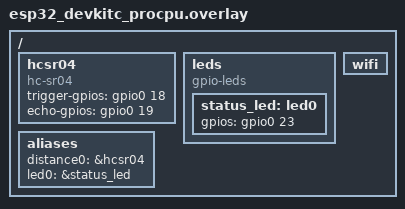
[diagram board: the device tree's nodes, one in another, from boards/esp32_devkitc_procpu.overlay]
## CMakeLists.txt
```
# SPDX-License-Identifier: Apache-2.0

cmake_minimum_required(VERSION 3.20.0)

find_package(Zephyr REQUIRED HINTS $ENV{ZEPHYR_BASE})
project(demo_wifi)

FILE(GLOB app_sources src/*.c)
target_sources(app PRIVATE ${app_sources})
```

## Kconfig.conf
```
# Required to get an IP address from DHCP
CONFIG_ESP32_WIFI_STA_AUTO_DHCPV4=y
CONFIG_ESP32_WIFI_ENABLE_WPA3_SAE=y
CONFIG_WIFI_ESP32_PM_NONE=y


# Use system heap (instead of runtime) for WiFi
CONFIG_ESP_WIFI_HEAP_SYSTEM=y
CONFIG_HEAP_MEM_POOL_SIZE=51200
```

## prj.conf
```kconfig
# Increase stack memory to avoid crashes
CONFIG_MAIN_STACK_SIZE=4096

# Enable WiFi
CONFIG_WIFI=y


# Networking config
CONFIG_NETWORKING=y
CONFIG_NET_IPV4=y
CONFIG_NET_IPV6=y
CONFIG_NET_TCP=y
CONFIG_NET_SOCKETS=y
CONFIG_ESP32_WIFI_ENABLE_WPA3_SAE=y
CONFIG_MQTT_LIB=y
CONFIG_NET_L2_WIFI_MGMT=y
CONFIG_NET_MGMT=y
CONFIG_NET_MGMT_EVENT=y
CONFIG_WIFI_ESP32=y
CONFIG_NET_IF_UNICAST_IPV4_ADDR_COUNT=1
CONFIG_NET_IF_MAX_IPV4_COUNT=1


# Get IPv4 address from DHCP
CONFIG_NET_DHCPV4=y

# Enable DNS resolver
CONFIG_DNS_RESOLVER=y

# How long to wait for e.g. DHCP to provide an IP address (seconds)
CONFIG_NET_CONFIG_INIT_TIMEOUT=30

# Network debug config
CONFIG_NET_LOG=y

# Enable Ethernet (required for WiFi)
CONFIG_NET_L2_ETHERNET=y

# Console Logs
CONFIG_CONSOLE=y
CONFIG_PRINTK=y


# Posix Threads
CONFIG_POSIX_API=y
CONFIG_THREAD_STACK_INFO=y
CONFIG_DYNAMIC_THREAD=y
CONFIG_DYNAMIC_THREAD_POOL_SIZE=8
CONFIG_POSIX_THREAD_THREADS_MAX=8

# Distance Sensor
CONFIG_GPIO=y
CONFIG_LOG=y
CONFIG_CBPRINTF_FP_SUPPORT=y
CONFIG_SENSOR=y
CONFIG_HC_SR04=y

# K_events
CONFIG_EVENTS=y

# UART
CONFIG_UART_CONSOLE=y
CONFIG_SERIAL=y

# JSON
CONFIG_JSON_LIBRARY=y
```

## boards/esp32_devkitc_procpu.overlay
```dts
#include <zephyr/dt-bindings/gpio/gpio.h>

/ {
    hcsr04: hcsr04 {
        compatible = "hc-sr04";
        status = "okay";

        trigger-gpios = <&gpio0 18 GPIO_ACTIVE_HIGH>;
        echo-gpios = <&gpio0 19 GPIO_ACTIVE_HIGH>;
        
    };

    leds {
        compatible = "gpio-leds";

        status_led: led0 {
            gpios = <&gpio0 23 GPIO_ACTIVE_HIGH>;
        };
    };

    wifi: wifi {
        status = "okay";
    };

    aliases {
        distance0 = &hcsr04;
        led0 = &status_led;
    };

   
};
```

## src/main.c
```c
#include <zephyr/kernel.h>
#include <semaphore.h>
#include <pthread.h>
#include <zephyr/net/net_if.h>
#include <zephyr/net/net_event.h>
#include <zephyr/net/wifi_mgmt.h>
#include <zephyr/net/dhcpv4.h>

#include "sync.h"
#include "mqtt.h"
#include "wifi.h"
#include "peripherals.h"
#include "uart.h"
#include "commands.h"

#define STACK_SIZE_MQTT 4096
#define STACK_SIZE_SENSOR 2048
#define STACK_SIZE_UART 4096
#define STACK_SIZE_COMM 4096

K_THREAD_STACK_DEFINE(mqtt_stack, STACK_SIZE_MQTT);
K_THREAD_STACK_DEFINE(distSen_stack, STACK_SIZE_SENSOR);
K_THREAD_STACK_DEFINE(uart_stack, STACK_SIZE_UART);
K_THREAD_STACK_DEFINE(comm_stack, STACK_SIZE_COMM);

struct k_thread ids[5];

int main(void)
{
    printk("Starting app\n");
    k_sem_init(&wifi_ready, 0, 1);
    k_sem_init(&ipv4_ready, 0, 1);
    wifi_init();
    wifi_connect();
    mqtt_init();


    k_thread_create(&ids[0],
                    mqtt_stack,
                    K_THREAD_STACK_SIZEOF(mqtt_stack),
                    thread_mqtt,
                    NULL, NULL, NULL,
                    2,           
                    0,          
                    K_NO_WAIT);
    
    k_thread_create(&ids[1],
                    distSen_stack,
                    K_THREAD_STACK_SIZEOF(distSen_stack),
                    thread_distSen,
                    NULL, NULL, NULL,
                    3,           
                    0,           
                    K_NO_WAIT);

    k_thread_create(&ids[2],
                    uart_stack,
                    K_THREAD_STACK_SIZEOF(uart_stack),
                    thread_uart,
                    NULL, NULL, NULL,
                    5,           
                    0,           
                    K_NO_WAIT);
    
    k_thread_create(&ids[3],
                    comm_stack,
                    K_THREAD_STACK_SIZEOF(comm_stack),
                    thread_comm,
                    NULL, NULL, NULL,
                    4,           
                    0,           
                    K_NO_WAIT);

    while (1) {
        k_sleep(K_SECONDS(2));
    }
}
```

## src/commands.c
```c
#include "commands.h"
void thread_comm(void *p1, void *p2, void *p3)
{
    char msg[256];
    static const struct gpio_dt_spec led = GPIO_DT_SPEC_GET(LED_NODE, gpios);
    if (!gpio_is_ready_dt(&led)) {
        printk("LED not ready\n");
        return;
    }
    gpio_pin_configure_dt(&led, GPIO_OUTPUT_INACTIVE);
    
    printk("Comm awaiting MQTT readyness...\n");
    k_event_wait(&sys_events,MQTT_READY_EVENT,false,K_FOREVER);

    while(1)
    {
        k_msgq_get(&comm_msgq, msg, K_FOREVER);
        printk("msg received: %s\n",msg);
        if (strcmp(msg, "ledOn") == 0) 
        {
            gpio_pin_set_dt(&led, 1);
            printk("LED ON\n");
        } 
        else if (strcmp(msg, "ledOff") == 0) {
            gpio_pin_set_dt(&led, 0);
            printk("LED OFF\n");
        }
    }
}
```

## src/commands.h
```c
#include <zephyr/kernel.h>
#include <zephyr/drivers/gpio.h>
#include <string.h>

#include "sync.h"

void thread_comm(void *p1, void *p2, void *p3);

#define LED_NODE DT_ALIAS(led0)
```

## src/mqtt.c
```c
#include "mqtt.h"
#include "sync.h"

static struct mqtt_client client;
static struct sockaddr_storage broker;
static uint32_t mqtt_rx_count = 0;

static uint8_t rx_buffer[256];
static uint8_t tx_buffer[256];
static uint16_t next_msg_id = 1;
char msgSend[MSG_SIZE];
char msgRec[MSG_SIZE];
bool mqttReady = false;

int mqtt_subscribe_topic(const char *topic);
int mqtt_publish_text(const char *topic,
                      const char *payload);
void parseComm(char *arr);
int get_text_field(const uint8_t *payload, size_t payload_len,
                   char *output, size_t output_len);

void build_json(char *out, size_t len,
                const char *id,
                const char *sender,
                const char *text)
{
    snprintf(out, len,
             "{\"id\":\"%s\",\"sender\":\"%s\",\"text\":\"%s\"}",
             id, sender, text);
}


                      
static void mqtt_event_handler(struct mqtt_client *client,
                               const struct mqtt_evt *evt)
{
    switch (evt->type) {
        case MQTT_EVT_CONNACK:
            if (evt->result == 0) 
                {
                    printk("MQTT connected!\n");
                    printk("POSTING TO EVENT=%p\n", &sys_events);
                    k_event_post(&sys_events, MQTT_READY_EVENT);
                    int rc = mqtt_subscribe_topic(UI_SUB);
                    printk("subscribe rc=%d\n", rc);
                    mqtt_publish_text(MCU_PUB, "{\"id\":\"mcu1\",\"sender\":\"mcu\",\"text\":\"MCU Joined\"}");
                    mqttReady = true;
                } 
            else 
                {printk("MQTT connection failed (%d)\n", evt->result);}
            break;

        case MQTT_EVT_DISCONNECT:
            printk("MQTT disconnected.\n");
            break;

        case MQTT_EVT_PUBLISH:
            printk("MQTT publish event #%u\n", ++mqtt_rx_count);
            uint8_t payload[256];
            char comm[256];
            int ret = mqtt_read_publish_payload(client,payload,sizeof(payload));
            if (ret < 0) {
                printk("read failed: %d\n", ret);
                break;
            }
            printk("msg received: %s\n",(char*)payload);
            int commRet = get_text_field(payload,strlen(payload),comm,sizeof(comm));
            if(!commRet) k_msgq_put(&comm_msgq, comm, K_FOREVER);
            break;
        
        default:
            break;
        }

}
    
void mqtt_init(void)
{
    mqtt_client_init(&client);

    client.evt_cb = mqtt_event_handler;
    client.client_id.utf8 = (uint8_t *)"esp32_client";
    client.client_id.size = strlen("esp32_client");
    client.password = NULL;
    client.user_name = NULL;
    client.keepalive = 45;
    client.protocol_version = MQTT_VERSION_3_1_1;
    client.rx_buf = rx_buffer;
    client.rx_buf_size = sizeof(rx_buffer);
    client.tx_buf = tx_buffer;
    client.tx_buf_size = sizeof(tx_buffer);

    struct sockaddr_in *broker4 =
        (struct sockaddr_in *)&broker;

    broker4->sin_family = AF_INET;
    broker4->sin_port = htons(MQTT_BROKER_PORT);

    zsock_inet_pton(AF_INET,
                    MQTT_BROKER_IP,
                    &broker4->sin_addr);

    client.broker = &broker;
    client.transport.type = MQTT_TRANSPORT_NON_SECURE;
}

static int mqtt_connect_to_broker(void)
{
    printk("Connecting to MQTT broker...\n");

    int ret = mqtt_connect(&client);

    if (ret) {
        printk("mqtt_connect() failed (%d)\n", ret);
    }

    return ret;
}

int mqtt_subscribe_topic(const char *topic)
{
    struct mqtt_topic sub_topic = {
        .topic = {
            .utf8 = (uint8_t *)topic,
            .size = strlen(topic),
        },
        .qos = MQTT_QOS_0_AT_MOST_ONCE,
    };

    const struct mqtt_subscription_list subs = {
        .list = &sub_topic,
        .list_count = 1,
        .message_id = next_msg_id++
    };

    return mqtt_subscribe(&client, &subs);
}

int mqtt_publish_text(const char *topic,
                      const char *payload)
{
    struct mqtt_publish_param param;
    
    memset(&param, 0, sizeof(param));
    param.message.topic.topic.utf8 = (uint8_t *)topic;
    param.message.topic.topic.size = strlen(topic);

    param.message.topic.qos = MQTT_QOS_0_AT_MOST_ONCE;
    param.message.payload.data = (uint8_t *)payload;
    param.message.payload.len = strlen(payload);

    param.message_id = 0;

    param.dup_flag = 0;
    param.retain_flag = 0;
    return mqtt_publish(&client, &param);
}

int get_text_field(const uint8_t *payload, size_t payload_len,
                   char *output, size_t output_len)
{
    const char key[] = "\"text\":\"";
    size_t key_len = sizeof(key) - 1;
    const uint8_t *start = NULL;
    for (size_t i = 0; i <= payload_len - key_len; i++) {
        if (memcmp(&payload[i], key, key_len) == 0) {
            start = &payload[i + key_len];
            break;
        }
    }
    if (start == NULL) {
        return -1; 
    }
    size_t i = 0;
    while (i < output_len - 1 &&
           (start[i] != '"') &&
           ((start + i) < (payload + payload_len))) {
        output[i] = start[i];
        i++;
    }
    output[i] = '\0';
    return 0;
}

void thread_mqtt(void *p1, void *p2, void *p3)
{
    printk("Awaiting Wifi connection...\n");
    k_sem_take(&wifi_ready,K_FOREVER);
    k_sem_take(&ipv4_ready,K_FOREVER);
    printk("Wifi connected. Starting MQTT...\n");

    if (mqtt_connect_to_broker()) {
        return;
    }

    while (1) {
        if(mqttReady)
        {
            char json[MSG_SIZE];
            k_msgq_get(&mqtt_msgq, msgSend, K_FOREVER);
            build_json(json,sizeof(json),MCU_ID,SENDER,msgSend);
            mqtt_publish_text(MCU_PUB, json);
        }
        mqtt_input(&client);
        mqtt_live(&client);
        k_sleep(K_MSEC(100));
    }

    return;
}
```

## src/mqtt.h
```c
#ifndef MQTT_H
#define MQTT_H

#include <pthread.h>
#include <semaphore.h>
#include <string.h>

#include <zephyr/net/socket.h>
#include <zephyr/net/mqtt.h>
#include <string.h>
#include <stdint.h>

#define MQTT_BROKER_IP   "10.208.10.41"
#define MQTT_BROKER_PORT 1883
#define MCU_PUB "mcu/pub"
#define UI_SUB "ui/pub"
#define MCU_ID "mcu1"
#define SENDER "mcu"

void mqtt_init(void);
void thread_mqtt(void *p1, void *p2, void *p3);

#endif
```

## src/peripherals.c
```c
#include "peripherals.h"

#define HCSR04_NODE DT_ALIAS(distance0)

void thread_distSen(void *p1, void *p2, void *p3)
{
    const struct device *sensor = DEVICE_DT_GET(HCSR04_NODE);

    if (!device_is_ready(sensor)) {
        printk("HC-SR04 Sensor Ready.\n");
        return;
    }

    printk("HC-SR04 sensor waiting MQTT readyness...\n");
    //printk("WAITING ON EVENT PTR=%p\n", &sys_events);
    k_event_wait(&sys_events,MQTT_READY_EVENT,false,K_FOREVER);
    printk("HC-SR04 sensor beginning measuring.\n");

    while (1) {
        struct sensor_value distancia;
        int ret;

        ret = sensor_sample_fetch(sensor);
        if (ret < 0) {
            printk("Error fetching sample: %d\n", ret);
            k_msleep(1700);
            continue;
        }

        ret = sensor_channel_get(sensor,
                                 SENSOR_CHAN_DISTANCE,
                                 &distancia);
        if (ret < 0) {
            printk("Error measuring Distance: %d\n", ret);
            k_msleep(1700);
            continue;
        }
        
        char msg[MSG_SIZE];

        snprintf(msg, sizeof(msg),
                "Distance: %d.%06d m",
                distancia.val1,
                distancia.val2);

        k_msgq_put(&mqtt_msgq, msg, K_FOREVER);

        k_msleep(1700);
    }

    return;
}
```

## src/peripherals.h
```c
#ifndef PERIPHERALS_H
#define PERIPHERALS_H

#include <zephyr/kernel.h>
#include <zephyr/device.h>
#include <zephyr/drivers/sensor.h>
#include <zephyr/sys/printk.h>

#include "sync.h"

void thread_distSen(void *p1, void *p2, void *p3);

#endif
```

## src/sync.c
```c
#include "sync.h"

struct k_sem wifi_ready;
struct k_sem ipv4_ready;
K_MSGQ_DEFINE(mqtt_msgq, MSG_SIZE, 10, 4);
K_MSGQ_DEFINE(comm_msgq, MSG_SIZE, 10, 4);
//K_MSGQ_DEFINE(mqtt_msgq, 256, 10, 4);
K_EVENT_DEFINE(sys_events);
```

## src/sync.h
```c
#ifndef SYNC_H
#define SYNC_H

#include <zephyr/kernel.h>

#define MSG_SIZE 256

extern struct k_sem  wifi_ready;
extern struct k_sem ipv4_ready;

extern struct k_msgq mqtt_msgq;
extern struct k_msgq comm_msgq;

extern struct k_event sys_events;
#define MQTT_READY_EVENT BIT(0)

#endif
```

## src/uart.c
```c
#include "uart.h"

void thread_uart(void *p1, void *p2, void *p3)
{
    const struct device *uart = DEVICE_DT_GET(UART_DEV_NODE);

    char buf[MSG_SIZE];
    int idx = 0;
    uint8_t c;

    if (!device_is_ready(uart)) {
        printk("UART device not ready!\n");
        return;
    }

    printk("UART awaiting MQTT readyness...\n");
    k_event_wait(&sys_events,MQTT_READY_EVENT,false,K_FOREVER);

    while (1) {
        if (uart_poll_in(uart, &c) == 0) {
            if (c == '\r' || c == '\n') {
                if (idx > 0) {
                    buf[idx] = '\0';
                    printk("\n");
                    k_msgq_put(&mqtt_msgq, buf, K_FOREVER);
                    idx = 0;
                }
                printk("uart> ");
            }
            else if ((c == '\b' || c == 127) && idx > 0) {
                idx--;
                printk("\b \b");
            }
            else if (idx < MSG_SIZE - 1) {
                buf[idx++] = c;
                printk("%c", c);
            }
        }
        k_sleep(K_MSEC(1));
    }
}
```

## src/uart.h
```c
#include <zephyr/device.h>
#include <zephyr/drivers/uart.h>

#include "sync.h"

void thread_uart(void *p1, void *p2, void *p3);

#define UART_DEV_NODE DT_CHOSEN(zephyr_console)
```

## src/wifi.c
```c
#include "wifi.h"

/* --- Event callback --- */

static struct net_mgmt_event_callback wifi_cb;
static struct net_mgmt_event_callback ipv4_cb;

void ipv4_event_handler(struct net_mgmt_event_callback *cb,
                               uint64_t event,
                               struct net_if *iface)
{
    printk("IP Received\n");
    k_sem_give(&ipv4_ready);
}

void wifi_event_handler(struct net_mgmt_event_callback *cb,
                               uint64_t event,
                               struct net_if *iface)
{
    printk("wifi is connected\n");
    k_sem_give(&wifi_ready);
}


void wifi_connect(void)
{
    struct net_if *iface = net_if_get_default();

    struct wifi_connect_req_params params = {
        .ssid = WIFI_SSID,
        .ssid_length = strlen(WIFI_SSID),
        .psk = WIFI_PSK,
        .psk_length = strlen(WIFI_PSK),
        .security = WIFI_SECURITY_TYPE_PSK,
        .channel = WIFI_CHANNEL_ANY,
    };

    printk("WiFi: connecting to %s...\n", WIFI_SSID);

    int ret = net_mgmt(NET_REQUEST_WIFI_CONNECT,
                       iface,
                       &params,
                       sizeof(params));
    
    printk("CONNECT RESULT: %d\n", ret);

    if (ret) {
        printk("WiFi: connect request failed (%d)\n", ret);
    }
}

/* --- public API --- */

void wifi_init(void)
{

    

    net_mgmt_init_event_callback(   &wifi_cb,
                                    wifi_event_handler,
                                    NET_EVENT_IF_UP |
                                    NET_EVENT_WIFI_CONNECT_RESULT);
    
    net_mgmt_init_event_callback(   &ipv4_cb,
                                    ipv4_event_handler,
                                    NET_EVENT_DNS_SERVER_ADD);
    
                                    

    net_mgmt_add_event_callback(&wifi_cb);
    net_mgmt_add_event_callback(&ipv4_cb);
}
```

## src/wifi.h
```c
#ifndef WIFI_H
#define WIFI_H

#include <zephyr/kernel.h>
#include <zephyr/net/net_if.h>
#include <zephyr/net/net_event.h>
#include <zephyr/net/wifi_mgmt.h>
#include <string.h>
#include <stdio.h>
#include <inttypes.h>

#include "sync.h"

#define WIFI_SSID       "Ricardo"
#define WIFI_PSK        "6sbtxuarg4itk7n"

void wifi_init(void);
void wifi_connect(void);

#endif
```
